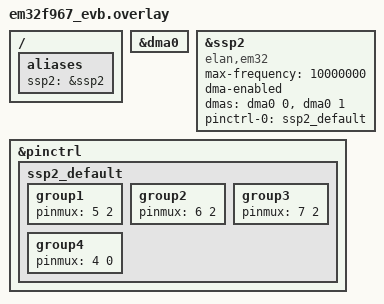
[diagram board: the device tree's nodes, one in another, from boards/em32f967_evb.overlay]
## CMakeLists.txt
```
cmake_minimum_required(VERSION 3.20.0)

find_package(Zephyr REQUIRED HINTS $ENV{ZEPHYR_BASE})
project(elan_ssp_test)

target_sources(app PRIVATE src/main.c)
target_sources(app PRIVATE src/ssp_test.c)
target_sources(app PRIVATE src/dma_test.c)
target_sources(app PRIVATE src/spi_debug_test.c)
```

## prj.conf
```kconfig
CONFIG_SPI=y
CONFIG_DMA=y
CONFIG_LOG=y
CONFIG_CONSOLE=y
CONFIG_UART_CONSOLE=y
CONFIG_SERIAL=y
CONFIG_PRINTK=y

# SPI Configuration
CONFIG_SPI_LOG_LEVEL_DBG=y
CONFIG_SPI_INIT_PRIORITY=80

# Enable interrupt and DMA modes for testing
CONFIG_SPI_EM32_INTERRUPT=y
CONFIG_SPI_EM32_DMA=y

# Enable DMA support
CONFIG_DMA=y
CONFIG_DMA_EM32F967=y

# Enable async SPI support
CONFIG_SPI_ASYNC=y

# DMA Configuration  
CONFIG_DMA_LOG_LEVEL_DBG=y

# Logging
CONFIG_LOG_DEFAULT_LEVEL=3
CONFIG_LOG_BACKEND_UART=y

# Test Configuration
CONFIG_MAIN_STACK_SIZE=2048
CONFIG_HEAP_MEM_POOL_SIZE=4096
```

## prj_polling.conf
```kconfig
# Polling-only configuration for debugging
CONFIG_MAIN_STACK_SIZE=2048
CONFIG_SYSTEM_WORKQUEUE_STACK_SIZE=2048

# Logging Configuration
CONFIG_LOG=y
CONFIG_LOG_DEFAULT_LEVEL=4
CONFIG_LOG_BACKEND_UART=y

# SPI Configuration
CONFIG_SPI_LOG_LEVEL_DBG=y
CONFIG_SPI_INIT_PRIORITY=80

# Force polling mode only - disable interrupt and DMA
CONFIG_SPI_EM32_INTERRUPT=n
CONFIG_SPI_EM32_DMA=n

# Disable DMA completely for this test
CONFIG_DMA=n

# Disable async SPI support
CONFIG_SPI_ASYNC=n

# GPIO and Pinctrl
CONFIG_GPIO=y
CONFIG_PINCTRL=y

# Clock control
CONFIG_CLOCK_CONTROL=y

# Enable console
CONFIG_CONSOLE=y
CONFIG_UART_CONSOLE=y
CONFIG_SERIAL=y

# Enable printk
CONFIG_PRINTK=y
CONFIG_EARLY_CONSOLE=y
```

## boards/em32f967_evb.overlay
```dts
/ {
    aliases {
        ssp2 = &ssp2;
    };
};

&dma0 {
    status = "okay";
};

&ssp2 {
    status = "okay";
    compatible = "elan,em32";
    max-frequency = <10000000>;
    dma-enabled;
    dmas = <&dma0 0>, <&dma0 1>;
    dma-names = "tx", "rx";

    pinctrl-0 = <&ssp2_default>;
    pinctrl-names = "default";
};

&pinctrl {
    ssp2_default: ssp2_default {
        group1 {
            /* SSP2 CLK - PB5 */
            pinmux = <5 2>;  /* Pin 5, MUX 2 */
        };
        group2 {
            /* SSP2 MISO - PB6 */
            pinmux = <6 2>;  /* Pin 6, MUX 2 */
        };
        group3 {
            /* SSP2 MOSI - PB7 */
            pinmux = <7 2>;  /* Pin 7, MUX 2 */
        };
        group4 {
            /* SSP2 CS - PB4 (optional, can be GPIO) */
            pinmux = <4 0>;  /* Pin 4, GPIO */
        };
    };
};
```

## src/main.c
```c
#include <zephyr/kernel.h>
#include <zephyr/device.h>
#include <zephyr/drivers/spi.h>
#include <zephyr/logging/log.h>
#include <zephyr/sys/printk.h>

LOG_MODULE_REGISTER(main, LOG_LEVEL_INF);

/* External test functions */
extern int ssp_basic_test(const struct device *spi_dev);
extern int ssp_loopback_test(const struct device *spi_dev);
extern int ssp_dma_test(const struct device *spi_dev);
extern int dma_memory_test(void);
extern int spi_debug_test_main(void);

#define SPI_NODE DT_NODELABEL(ssp2)

int main(void)
{
    const struct device *spi_dev;
    int ret;

    printk("\n=== ELAN EM32F967 SSP/DMA Test Suite ===\n");
    printk("Elan EM32 SSP Driver with DMA Support\n\n");

    /* Get SPI device */
    spi_dev = DEVICE_DT_GET(SPI_NODE);
    if (!device_is_ready(spi_dev)) {
        LOG_ERR("SPI device not ready");
        return -1;
    }

    LOG_INF("SPI device ready: %s", spi_dev->name);

    /* Debug Tests: Comprehensive SPI/DMA debugging */
    printk("\n--- Debug Tests: SPI/DMA Analysis ---\n");
    spi_debug_test_main();

    /* Test 1: Basic SPI functionality */
    printk("\n--- Test 1: Basic SPI Transfer ---\n");
    ret = ssp_basic_test(spi_dev);
    if (ret == 0) {
        printk("✓ Basic SPI test PASSED\n");
    } else {
        printk("✗ Basic SPI test FAILED: %d\n", ret);
    }

    /* Test 2: SPI Loopback test */
    printk("\n--- Test 2: SPI Loopback Test ---\n");
    ret = ssp_loopback_test(spi_dev);
    if (ret == 0) {
        printk("✓ Loopback test PASSED\n");
    } else {
        printk("✗ Loopback test FAILED: %d\n", ret);
    }

    /* Test 3: DMA Memory-to-Memory */
    printk("\n--- Test 3: DMA Memory Test ---\n");
    ret = dma_memory_test();
    if (ret == 0) {
        printk("✓ DMA memory test PASSED\n");
    } else {
        printk("✗ DMA memory test FAILED: %d\n", ret);
    }

    /* Test 4: SPI with DMA */
    printk("\n--- Test 4: SPI DMA Transfer ---\n");
    ret = ssp_dma_test(spi_dev);
    if (ret == 0) {
        printk("✓ SPI DMA test PASSED\n");
    } else {
        printk("✗ SPI DMA test FAILED: %d\n", ret);
    }

    printk("\n=== Test Suite Complete ===\n");
    
    /* Keep running for continuous testing */
    while (1) {
        k_sleep(K_SECONDS(10));
        printk("System running... (press reset to restart tests)\n");
    }

    return 0;
}
```

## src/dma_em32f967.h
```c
#ifndef DMA_EM32F967_H
#define DMA_EM32F967_H

#include <zephyr/kernel.h>
#include <zephyr/device.h>
#include <zephyr/drivers/dma.h>

/* DMA Channel Definitions */
typedef enum {
    DMACH0 = 0,
    DMACH1 = 1,
    DMACH2 = 2,
    DMACH3 = 3,
    DMACH4 = 4,
    DMACH_MAX = 5
} DMAChannel;

/* DMA Width Definitions */
typedef enum {
    SRC8DST8   = 0x00,
    SRC16DST16 = 0x11,
    SRC32DST32 = 0x22
} DMAWidthDef;

/* DMA Handshake Definitions */
typedef enum {
    MEMORY_MEMORY    = 0x00,
    MEMORY_UART1_TX  = 0x01,
    UART1_MEMORY_RX  = 0x02,
    MEMORY_SSP2_TX   = 0x06,
    SSP2_MEMORY_RX   = 0x07,
    MEMORY_SPI1_TX   = 0x08,
    SPI1_MEMORY_RX   = 0x09
} DMAHandShake;

/* DMA API Functions */
uint32_t RequestDMAChannel(DMAChannel channel);
void ReleaseAllDMA(void);
uint32_t MEMDMASetting(DMAChannel channel, uint32_t SrcAddr, uint32_t DstAddr, 
                       uint32_t Length, DMAWidthDef SDWidth);
uint32_t PHERDMASetting(DMAChannel channel, DMAHandShake HSnumber, 
                        uint32_t MemAddr, uint32_t Length, DMAWidthDef SDWidth);
void DMAStart(DMAChannel channel);
bool CheckDMADone(DMAChannel channel);
void WaitDMADone(DMAChannel channel);

/* SSP DMA Functions */
void SPI2DMASetStart(uint32_t TXAddr, uint32_t RXAddr, uint32_t length);
void SPI2DMASetStop(void);
void WaitSPI2DMADone(void);
bool CheckSPI2DMADone(void);

#endif /* DMA_EM32F967_H */
```

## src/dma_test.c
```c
#include <zephyr/kernel.h>
#include <zephyr/logging/log.h>
#include <zephyr/sys/printk.h>
#include <zephyr/drivers/dma.h>
#include <string.h>

LOG_MODULE_REGISTER(dma_test, LOG_LEVEL_DBG);

int dma_memory_test(void)
{
    LOG_INF("DMA memory test - SKIPPED (requires DMA device tree configuration)");
    LOG_INF("Note: Zephyr's PL022 SPI driver will automatically use DMA for large transfers");
    return 0;
}
```

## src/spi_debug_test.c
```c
/*
 * Copyright (c) 2025 Elan Microelectronics Corp.
 * SPDX-License-Identifier: Apache-2.0
 */

#include <zephyr/kernel.h>
#include <zephyr/device.h>
#include <zephyr/drivers/spi.h>
#include <zephyr/drivers/dma.h>
#include <zephyr/logging/log.h>
#include <zephyr/sys/printk.h>

LOG_MODULE_REGISTER(spi_debug_test, LOG_LEVEL_DBG);

#define SPI_DEVICE_NODE DT_NODELABEL(ssp2)
#define DMA_DEVICE_NODE DT_NODELABEL(dma0)

/* Test data patterns */
static uint8_t tx_buffer_small[16] = {
	0x01, 0x02, 0x03, 0x04, 0x05, 0x06, 0x07, 0x08,
	0x09, 0x0A, 0x0B, 0x0C, 0x0D, 0x0E, 0x0F, 0x10
};

static uint8_t rx_buffer_small[16];

static uint8_t tx_buffer_large[256];
static uint8_t rx_buffer_large[256];

/* Test configuration */
static struct spi_config spi_cfg = {
	.operation = SPI_WORD_SET(8) | SPI_TRANSFER_MSB | SPI_MODE_CPOL | SPI_MODE_CPHA,
	.frequency = 1000000, /* 1 MHz */
	.slave = 0,
};

/* Test results */
struct test_result {
	const char *name;
	int result;
	uint32_t duration_ms;
};

static struct test_result test_results[10];
static int test_count = 0;

static void record_test_result(const char *name, int result, uint32_t duration_ms)
{
	if (test_count < ARRAY_SIZE(test_results)) {
		test_results[test_count].name = name;
		test_results[test_count].result = result;
		test_results[test_count].duration_ms = duration_ms;
		test_count++;
	}
}

static void print_test_summary(void)
{
	printk("\n=== SPI Debug Test Summary ===\n");
	for (int i = 0; i < test_count; i++) {
		printk("%-25s: %s (%d ms)\n", 
		       test_results[i].name,
		       test_results[i].result == 0 ? "PASS" : "FAIL",
		       test_results[i].duration_ms);
	}
	printk("===============================\n");
}

static void dump_spi_registers(const struct device *spi_dev)
{
	/* Access SPI registers directly - SSP2 base address is 0x40013000 */
	volatile uint32_t *ssp_base = (volatile uint32_t *)0x40013000;

	LOG_INF("=== SPI Register Dump ===");
	LOG_INF("SSP_CR0   (0x00): 0x%08x", ssp_base[0x00/4]);
	LOG_INF("SSP_CR1   (0x04): 0x%08x", ssp_base[0x04/4]);
	LOG_INF("SSP_DR    (0x08): 0x%08x", ssp_base[0x08/4]);
	LOG_INF("SSP_SR    (0x0C): 0x%08x", ssp_base[0x0C/4]);
	LOG_INF("SSP_CPSR  (0x10): 0x%08x", ssp_base[0x10/4]);
	LOG_INF("SSP_IMSC  (0x14): 0x%08x", ssp_base[0x14/4]);
	LOG_INF("SSP_RIS   (0x18): 0x%08x", ssp_base[0x18/4]);
	LOG_INF("SSP_MIS   (0x1C): 0x%08x", ssp_base[0x1C/4]);
	LOG_INF("SSP_ICR   (0x20): 0x%08x", ssp_base[0x20/4]);
	LOG_INF("SSP_DMACR (0x24): 0x%08x", ssp_base[0x24/4]);
	LOG_INF("========================");
}

static void dump_dma_registers(const struct device *dma_dev)
{
	/* This would need to be implemented with actual register access */
	LOG_INF("=== DMA Register Dump ===");
	LOG_INF("Note: Register dump requires direct register access");
	LOG_INF("========================");
}

static int test_spi_polling_mode(const struct device *spi_dev)
{
	uint32_t start_time = k_uptime_get_32();
	int ret;

	LOG_INF("=== Testing SPI Polling Mode ===");
	LOG_INF("Note: This test should use polling mode, but driver may still use interrupts");

	/* Prepare test data */
	for (int i = 0; i < sizeof(tx_buffer_small); i++) {
		tx_buffer_small[i] = i + 1;
	}
	memset(rx_buffer_small, 0, sizeof(rx_buffer_small));

	struct spi_buf tx_buf = {
		.buf = tx_buffer_small,
		.len = sizeof(tx_buffer_small)
	};
	struct spi_buf rx_buf = {
		.buf = rx_buffer_small,
		.len = sizeof(rx_buffer_small)
	};
	struct spi_buf_set tx_bufs = {
		.buffers = &tx_buf,
		.count = 1
	};
	struct spi_buf_set rx_bufs = {
		.buffers = &rx_buf,
		.count = 1
	};

	LOG_INF("TX data: %02x %02x %02x %02x %02x %02x %02x %02x",
		tx_buffer_small[0], tx_buffer_small[1], tx_buffer_small[2], tx_buffer_small[3],
		tx_buffer_small[4], tx_buffer_small[5], tx_buffer_small[6], tx_buffer_small[7]);

	ret = spi_transceive(spi_dev, &spi_cfg, &tx_bufs, &rx_bufs);

	uint32_t duration = k_uptime_get_32() - start_time;

	if (ret == 0) {
		LOG_INF("RX data: %02x %02x %02x %02x %02x %02x %02x %02x",
			rx_buffer_small[0], rx_buffer_small[1], rx_buffer_small[2], rx_buffer_small[3],
			rx_buffer_small[4], rx_buffer_small[5], rx_buffer_small[6], rx_buffer_small[7]);
		LOG_INF("Polling mode test PASSED");
	} else {
		LOG_ERR("Polling mode test FAILED: %d", ret);
		dump_spi_registers(spi_dev);
	}

	record_test_result("SPI Polling Mode", ret, duration);
	return ret;
}

static volatile bool async_complete = false;
static volatile int async_result = 0;

static void spi_async_callback(const struct device *dev, int result, void *data)
{
	LOG_DBG("SPI async callback: result=%d", result);
	async_result = result;
	async_complete = true;
}

static int test_spi_interrupt_mode(const struct device *spi_dev)
{
	uint32_t start_time = k_uptime_get_32();
	int ret;

	LOG_INF("=== Testing SPI Interrupt Mode ===");

	/* Prepare test data */
	for (int i = 0; i < sizeof(tx_buffer_small); i++) {
		tx_buffer_small[i] = 0xA0 + i;
	}
	memset(rx_buffer_small, 0, sizeof(rx_buffer_small));

	struct spi_buf tx_buf = {
		.buf = tx_buffer_small,
		.len = sizeof(tx_buffer_small)
	};
	struct spi_buf rx_buf = {
		.buf = rx_buffer_small,
		.len = sizeof(rx_buffer_small)
	};
	struct spi_buf_set tx_bufs = {
		.buffers = &tx_buf,
		.count = 1
	};
	struct spi_buf_set rx_bufs = {
		.buffers = &rx_buf,
		.count = 1
	};

	async_complete = false;
	async_result = 0;

	LOG_INF("TX data: %02x %02x %02x %02x %02x %02x %02x %02x",
		tx_buffer_small[0], tx_buffer_small[1], tx_buffer_small[2], tx_buffer_small[3],
		tx_buffer_small[4], tx_buffer_small[5], tx_buffer_small[6], tx_buffer_small[7]);

#ifdef CONFIG_SPI_ASYNC
	ret = spi_transceive_cb(spi_dev, &spi_cfg, &tx_bufs, &rx_bufs, spi_async_callback, NULL);
	if (ret == 0) {
		/* Wait for completion with timeout */
		int timeout_count = 0;
		while (!async_complete && timeout_count < 1000) {
			k_msleep(1);
			timeout_count++;
		}
		
		if (!async_complete) {
			LOG_ERR("Interrupt mode test TIMEOUT");
			ret = -ETIMEDOUT;
		} else {
			ret = async_result;
		}
	}
#else
	LOG_WRN("SPI_ASYNC not enabled, skipping interrupt test");
	ret = -ENOTSUP;
#endif

	uint32_t duration = k_uptime_get_32() - start_time;

	if (ret == 0) {
		LOG_INF("RX data: %02x %02x %02x %02x %02x %02x %02x %02x",
			rx_buffer_small[0], rx_buffer_small[1], rx_buffer_small[2], rx_buffer_small[3],
			rx_buffer_small[4], rx_buffer_small[5], rx_buffer_small[6], rx_buffer_small[7]);
		LOG_INF("Interrupt mode test PASSED");
	} else {
		LOG_ERR("Interrupt mode test FAILED: %d", ret);
		dump_spi_registers(spi_dev);
	}

	record_test_result("SPI Interrupt Mode", ret, duration);
	return ret;
}

static int test_dma_controller(const struct device *dma_dev)
{
	uint32_t start_time = k_uptime_get_32();
	int ret = 0;

	LOG_INF("=== Testing DMA Controller ===");

	if (!device_is_ready(dma_dev)) {
		LOG_ERR("DMA device not ready");
		ret = -ENODEV;
	} else {
		LOG_INF("DMA controller is ready");
		
		/* Test DMA status */
		struct dma_status status;
		ret = dma_get_status(dma_dev, 0, &status);
		if (ret == 0) {
			LOG_INF("DMA channel 0 status: busy=%d", status.busy);
		} else {
			LOG_ERR("Failed to get DMA status: %d", ret);
		}
	}

	uint32_t duration = k_uptime_get_32() - start_time;
	record_test_result("DMA Controller", ret, duration);
	return ret;
}

static int test_spi_dma_mode(const struct device *spi_dev)
{
	uint32_t start_time = k_uptime_get_32();
	int ret;

	LOG_INF("=== Testing SPI DMA Mode ===");

	/* Prepare large test data */
	for (int i = 0; i < sizeof(tx_buffer_large); i++) {
		tx_buffer_large[i] = (i & 0xFF);
	}
	memset(rx_buffer_large, 0, sizeof(rx_buffer_large));

	struct spi_buf tx_buf = {
		.buf = tx_buffer_large,
		.len = sizeof(tx_buffer_large)
	};
	struct spi_buf rx_buf = {
		.buf = rx_buffer_large,
		.len = sizeof(rx_buffer_large)
	};
	struct spi_buf_set tx_bufs = {
		.buffers = &tx_buf,
		.count = 1
	};
	struct spi_buf_set rx_bufs = {
		.buffers = &rx_buf,
		.count = 1
	};

	LOG_INF("TX data (first 8): %02x %02x %02x %02x %02x %02x %02x %02x",
		tx_buffer_large[0], tx_buffer_large[1], tx_buffer_large[2], tx_buffer_large[3],
		tx_buffer_large[4], tx_buffer_large[5], tx_buffer_large[6], tx_buffer_large[7]);

	ret = spi_transceive(spi_dev, &spi_cfg, &tx_bufs, &rx_bufs);

	uint32_t duration = k_uptime_get_32() - start_time;

	if (ret == 0) {
		LOG_INF("RX data (first 8): %02x %02x %02x %02x %02x %02x %02x %02x",
			rx_buffer_large[0], rx_buffer_large[1], rx_buffer_large[2], rx_buffer_large[3],
			rx_buffer_large[4], rx_buffer_large[5], rx_buffer_large[6], rx_buffer_large[7]);
		LOG_INF("DMA mode test PASSED");
	} else {
		LOG_ERR("DMA mode test FAILED: %d", ret);
		dump_spi_registers(spi_dev);
	}

	record_test_result("SPI DMA Mode", ret, duration);
	return ret;
}

int spi_debug_test_main(void)
{
	const struct device *spi_dev = DEVICE_DT_GET(SPI_DEVICE_NODE);
	const struct device *dma_dev = DEVICE_DT_GET_OR_NULL(DMA_DEVICE_NODE);

	printk("\n=== EM32F967 SPI Debug Test Suite ===\n");
	printk("SPI Device: %s\n", spi_dev->name);
	if (dma_dev) {
		printk("DMA Device: %s\n", dma_dev->name);
	} else {
		printk("DMA Device: Not available\n");
	}

	if (!device_is_ready(spi_dev)) {
		LOG_ERR("SPI device not ready");
		return -ENODEV;
	}

	/* Test 1: SPI Polling Mode */
	test_spi_polling_mode(spi_dev);
	k_msleep(100);

	/* Test 2: DMA Controller */
	if (dma_dev) {
		test_dma_controller(dma_dev);
		k_msleep(100);
	}

	/* Test 3: SPI Interrupt Mode */
	test_spi_interrupt_mode(spi_dev);
	k_msleep(100);

	/* Test 4: SPI DMA Mode */
	test_spi_dma_mode(spi_dev);
	k_msleep(100);

	/* Print summary */
	print_test_summary();

	return 0;
}
```

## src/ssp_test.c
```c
#include <zephyr/kernel.h>
#include <zephyr/device.h>
#include <zephyr/drivers/spi.h>
#include <zephyr/logging/log.h>
#include <zephyr/sys/printk.h>
#include <string.h>

LOG_MODULE_REGISTER(ssp_test, LOG_LEVEL_DBG);

int ssp_basic_test(const struct device *spi_dev)
{
    struct spi_config spi_cfg = {
        .frequency = 1000000,  /* 1MHz */
        .operation = SPI_WORD_SET(8) | SPI_TRANSFER_MSB | SPI_MODE_CPOL | SPI_MODE_CPHA,
        .slave = 0,
        .cs = NULL,
    };

    uint8_t tx_data[] = {0x01, 0x02, 0x03, 0x04, 0x05};
    uint8_t rx_data[sizeof(tx_data)] = {0};

    struct spi_buf tx_buf = {
        .buf = tx_data,
        .len = sizeof(tx_data),
    };

    struct spi_buf rx_buf = {
        .buf = rx_data,
        .len = sizeof(rx_data),
    };

    struct spi_buf_set tx_bufs = {
        .buffers = &tx_buf,
        .count = 1,
    };

    struct spi_buf_set rx_bufs = {
        .buffers = &rx_buf,
        .count = 1,
    };

    LOG_INF("Starting basic SPI transfer");
    LOG_INF("TX data: %02x %02x %02x %02x %02x", 
            tx_data[0], tx_data[1], tx_data[2], tx_data[3], tx_data[4]);

    int ret = spi_transceive(spi_dev, &spi_cfg, &tx_bufs, &rx_bufs);
    if (ret != 0) {
        LOG_ERR("SPI transceive failed: %d", ret);
        return ret;
    }

    LOG_INF("RX data: %02x %02x %02x %02x %02x", 
            rx_data[0], rx_data[1], rx_data[2], rx_data[3], rx_data[4]);

    return 0;
}

int ssp_loopback_test(const struct device *spi_dev)
{
    struct spi_config spi_cfg = {
        .frequency = 2000000,  /* 2MHz */
        .operation = SPI_WORD_SET(8) | SPI_TRANSFER_MSB,
        .slave = 0,
        .cs = NULL,
    };

    uint8_t test_pattern[] = {0xAA, 0x55, 0xFF, 0x00, 0x5A, 0xA5, 0x33, 0xCC};
    uint8_t rx_data[sizeof(test_pattern)] = {0};

    struct spi_buf tx_buf = {
        .buf = test_pattern,
        .len = sizeof(test_pattern),
    };

    struct spi_buf rx_buf = {
        .buf = rx_data,
        .len = sizeof(rx_data),
    };

    struct spi_buf_set tx_bufs = {
        .buffers = &tx_buf,
        .count = 1,
    };

    struct spi_buf_set rx_bufs = {
        .buffers = &rx_buf,
        .count = 1,
    };

    LOG_INF("Starting loopback test (connect MOSI to MISO)");

    int ret = spi_transceive(spi_dev, &spi_cfg, &tx_bufs, &rx_bufs);
    if (ret != 0) {
        LOG_ERR("SPI loopback failed: %d", ret);
        return ret;
    }

    /* Verify loopback data */
    bool match = true;
    for (int i = 0; i < sizeof(test_pattern); i++) {
        if (test_pattern[i] != rx_data[i]) {
            LOG_ERR("Mismatch at index %d: TX=0x%02x, RX=0x%02x", 
                    i, test_pattern[i], rx_data[i]);
            match = false;
        }
    }

    if (match) {
        LOG_INF("Loopback test successful - all data matched");
        return 0;
    } else {
        LOG_ERR("Loopback test failed - data mismatch");
        return -1;
    }
}

int ssp_dma_test(const struct device *spi_dev)
{
    struct spi_config spi_cfg = {
        .frequency = 4000000,  /* 4MHz */
        .operation = SPI_WORD_SET(8) | SPI_TRANSFER_MSB,
        .slave = 0,
        .cs = NULL,
    };

    /* Large buffer to trigger DMA */
    uint8_t tx_data[256];
    uint8_t rx_data[256] = {0};

    /* Fill TX buffer with pattern */
    for (int i = 0; i < sizeof(tx_data); i++) {
        tx_data[i] = i & 0xFF;
    }

    struct spi_buf tx_buf = {
        .buf = tx_data,
        .len = sizeof(tx_data),
    };

    struct spi_buf rx_buf = {
        .buf = rx_data,
        .len = sizeof(rx_data),
    };

    struct spi_buf_set tx_bufs = {
        .buffers = &tx_buf,
        .count = 1,
    };

    struct spi_buf_set rx_bufs = {
        .buffers = &rx_buf,
        .count = 1,
    };

    LOG_INF("Starting DMA transfer test (256 bytes)");

    uint32_t start_time = k_cycle_get_32();
    int ret = spi_transceive(spi_dev, &spi_cfg, &tx_bufs, &rx_bufs);
    uint32_t end_time = k_cycle_get_32();

    if (ret != 0) {
        LOG_ERR("SPI DMA transfer failed: %d", ret);
        return ret;
    }

    uint32_t cycles = end_time - start_time;
    LOG_INF("DMA transfer completed in %u cycles", cycles);

    /* Verify first and last few bytes */
    LOG_INF("First 8 RX bytes: %02x %02x %02x %02x %02x %02x %02x %02x",
            rx_data[0], rx_data[1], rx_data[2], rx_data[3],
            rx_data[4], rx_data[5], rx_data[6], rx_data[7]);

    LOG_INF("Last 8 RX bytes: %02x %02x %02x %02x %02x %02x %02x %02x",
            rx_data[248], rx_data[249], rx_data[250], rx_data[251],
            rx_data[252], rx_data[253], rx_data[254], rx_data[255]);

    return 0;
}
```
